# VPAC0_PAR_VPAC_VISS0_S_VBUSP_VISS_FCP2_FCC_VBUSP_FLEXCC_C8G8 register map
Vendor: Texas Instruments
Peripheral module from a debugger description file (folder J721S2).
Registers are 32-bit, read-write, reset 0x0 unless marked. A register's access mark holds for its fields unless they carry their own. Offsets are as the file gives them; lines under a group give offsets from that group; [hi:lo] are bit positions; {n}, {i} and the like mark numbered series; 'fields as' and 'values as' point back to an identical list; <NAME> marks a mode.

## VPAC0_PAR_VPAC_VISS0_S_VBUSP_VISS_FCP2_FCC_VBUSP_FLEXCC_C8G8
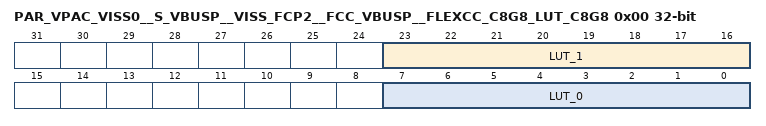
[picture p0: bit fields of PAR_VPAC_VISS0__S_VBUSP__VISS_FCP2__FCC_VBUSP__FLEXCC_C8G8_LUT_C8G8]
0x00 PAR_VPAC_VISS0__S_VBUSP__VISS_FCP2__FCC_VBUSP__FLEXCC_C8G8_LUT_C8G8 — Memory for 12to8 LUT
  [23:16] LUT_1 — Bank-1
  [7:0] LUT_0 — Bank-0
